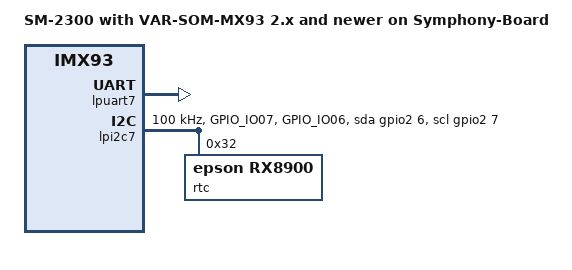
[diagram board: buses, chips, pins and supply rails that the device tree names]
/dts-v1/;

#include "imx93-var-som.dtsi"
#include "imx93-var-som-symphony.dtsi"

/ {
    /* VAR-SOM-MX93D_V2_1700C_2048R_16G_AC_EC_TP_WBD_ET */
    model = "SM-2300 with VAR-SOM-MX93 2.x and newer on Symphony-Board";

    pinctrl_lpi2c7: lpi2c7grp {
        fsl,pins = <
            MX93_PAD_GPIO_IO07__LPI2C7_SCL          0x40000b9e
            MX93_PAD_GPIO_IO06__LPI2C7_SDA          0x40000b9e
        >;
    };

    pinctrl_lpi2c7_gpio: lpi2c7grp-gpio {
        fsl,pins = <
            MX93_PAD_GPIO_IO07__GPIO2_IO07          0x40000b9e
            MX93_PAD_GPIO_IO06__GPIO2_IO06          0x40000b9e
        >;
    };
};

&lpuart7 {
    status = "okay";
};


&lpi2c7 {
    #address-cells = <1>;
    #size-cells = <0>;
    clock-frequency = <100000>;
    pinctrl-names = "default", "sleep", "gpio";
    pinctrl-0 = <&pinctrl_lpi2c7>;
    pinctrl-1 = <&pinctrl_lpi2c7_gpio>;
    pinctrl-2 = <&pinctrl_lpi2c7_gpio>;
    scl-gpios = <&gpio2 7 GPIO_ACTIVE_HIGH>;
    sda-gpios = <&gpio2 6 GPIO_ACTIVE_HIGH>;
    status = "okay";
    
    rtc: rtc@32 {
        compatible = "epson,rx8900";
        reg = <0x32>;
        epson,vdet-disable;

        //Wake ISR
        // interrupt-parent = <&gpio5>;
        // interrupts = <3>;
    };
/*
    eeprom@50 {
        compatible = "atmel,24c64";
        reg = <0x50>;
        
        label = "Config FRAM";
        pagesize = <8192>;
        size     = <8192>;
        address-width = <16>;
        num-addresses = <1>;
    };

    eeprom@51 {
        compatible = "st,24c64", "atmel,24c64";
        reg = <0x51>;
         
        label = "Cal EEPROM";
        pagesize = <32>;
        size     = <8192>;
        address-width = <16>;
        num-addresses = <1>;
    };
*/
};
